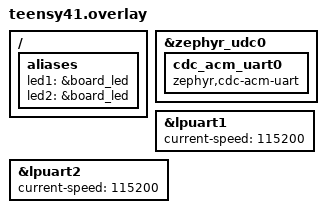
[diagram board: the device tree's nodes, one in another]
&zephyr_udc0 {
    cdc_acm_uart0: cdc_acm_uart0 {
        compatible = "zephyr,cdc-acm-uart";
    };
};

&lpuart1 {
	status = "okay";
	current-speed = < 115200 >;
};

&lpuart2 {
	status = "okay";
	current-speed = < 115200 >;
};

/ {
    aliases {
        led1 = &board_led;
        led2 = &board_led;
    };
};
